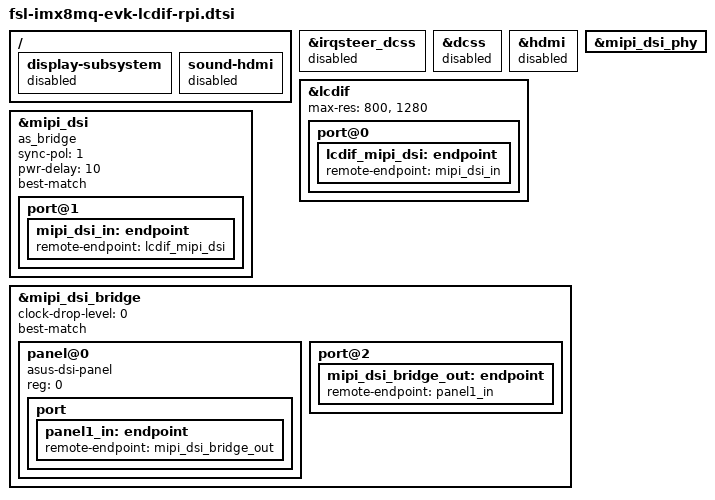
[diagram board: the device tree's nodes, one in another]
/*
 * Copyright 2018 NXP
 *
 * This program is free software; you can redistribute it and/or
 * modify it under the terms of the GNU General Public License
 * as published by the Free Software Foundation; either version 2
 * of the License, or (at your option) any later version.
 *
 * This program is distributed in the hope that it will be useful,
 * but WITHOUT ANY WARRANTY; without even the implied warranty of
 * MERCHANTABILITY or FITNESS FOR A PARTICULAR PURPOSE.  See the
 * GNU General Public License for more details.
 */

/ {
	display-subsystem {
		status = "disabled";
	};

	sound-hdmi {
		status = "disabled";
	};
};

&irqsteer_dcss {
	status = "disabled";
};

&dcss {
	status = "disabled";
};

&hdmi {
	status = "disabled";
};

&lcdif {
	status = "okay";
	max-res = <800>, <1280>;

	port@0 {
		lcdif_mipi_dsi: endpoint {
			remote-endpoint = <&mipi_dsi_in>;
		};
	};
};

&mipi_dsi_phy {
	status = "okay";
};

&mipi_dsi {
	status = "okay";
	as_bridge;
	sync-pol = <1>;
	pwr-delay = <10>;
	best-match;

	port@1 {
		mipi_dsi_in: endpoint  {
			remote-endpoint = <&lcdif_mipi_dsi>;
		};
	};
};

&mipi_dsi_bridge {
	status = "okay";
	clock-drop-level = <0>;
	best-match;

	panel@0 {
		compatible = "asus-dsi-panel";
		reg = <0>;

		port {
			panel1_in: endpoint {
				remote-endpoint = <&mipi_dsi_bridge_out>;
			};
		};
	};

	port@2 {
		mipi_dsi_bridge_out: endpoint {
			remote-endpoint = <&panel1_in>;
		};
	};
};

